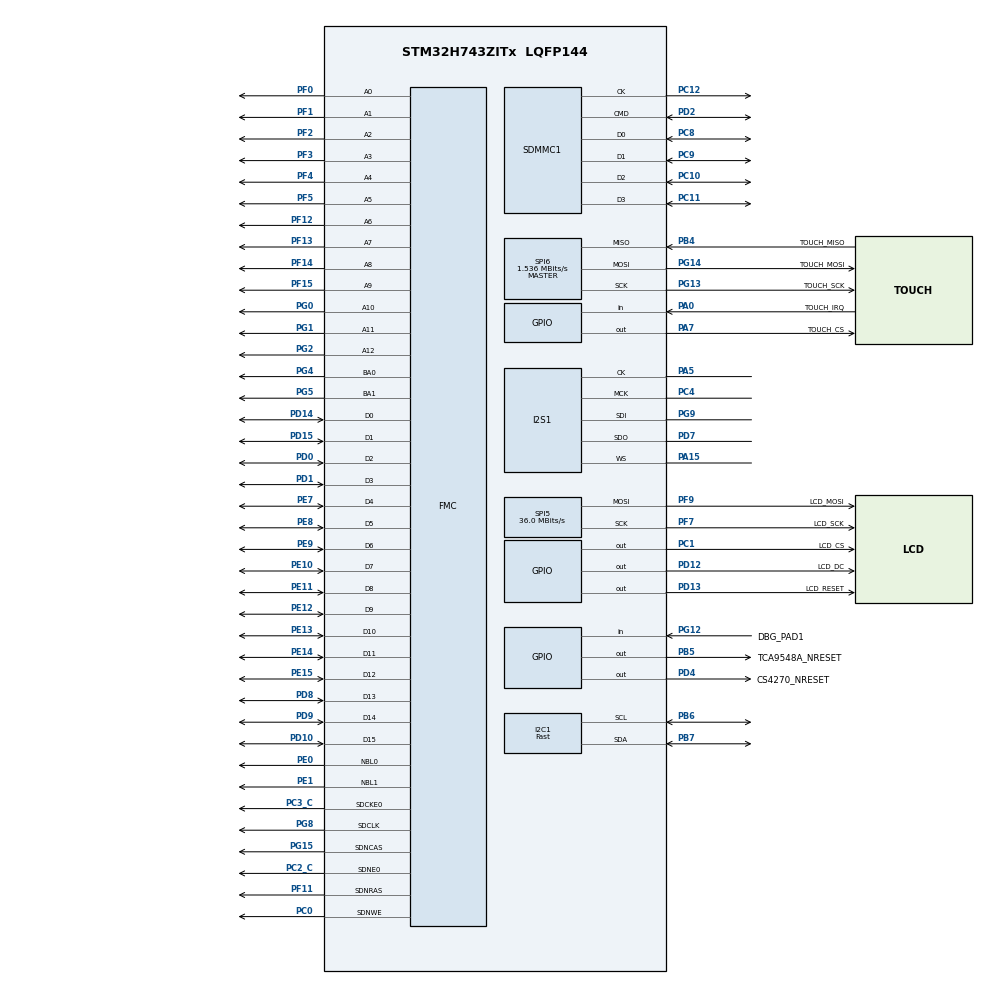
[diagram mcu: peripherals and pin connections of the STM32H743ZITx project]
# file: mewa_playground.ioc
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CORTEX_M7.AccessPermission-Cortex_Memory_Protection_Unit_Region0_Settings=MPU_REGION_FULL_ACCESS
CORTEX_M7.AccessPermission_S-Cortex_Memory_Protection_Unit_Region1_Settings_S=MPU_REGION_FULL_ACCESS
CORTEX_M7.AccessPermission_S-Cortex_Memory_Protection_Unit_Region2_Settings_S=MPU_REGION_FULL_ACCESS
CORTEX_M7.BaseAddress-Cortex_Memory_Protection_Unit_Region0_Settings=0xC0000000
CORTEX_M7.BaseAddress_S-Cortex_Memory_Protection_Unit_Region1_Settings_S=0x24000000
CORTEX_M7.BaseAddress_S-Cortex_Memory_Protection_Unit_Region2_Settings_S=0xC0000000
CORTEX_M7.CPU_DCache=Enabled
CORTEX_M7.CPU_ICache=Enabled
CORTEX_M7.DisableExec-Cortex_Memory_Protection_Unit_Region0_Settings=MPU_INSTRUCTION_ACCESS_DISABLE
CORTEX_M7.DisableExec_S-Cortex_Memory_Protection_Unit_Region1_Settings_S=MPU_INSTRUCTION_ACCESS_DISABLE
CORTEX_M7.DisableExec_S-Cortex_Memory_Protection_Unit_Region2_Settings_S=MPU_INSTRUCTION_ACCESS_DISABLE
CORTEX_M7.Enable-Cortex_Memory_Protection_Unit_Region0_Settings=MPU_REGION_ENABLE
CORTEX_M7.Enable_S-Cortex_Memory_Protection_Unit_Region1_Settings_S=MPU_REGION_ENABLE
CORTEX_M7.Enable_S-Cortex_Memory_Protection_Unit_Region2_Settings_S=MPU_REGION_ENABLE
CORTEX_M7.IsBufferable_S-Cortex_Memory_Protection_Unit_Region1_Settings_S=MPU_ACCESS_BUFFERABLE
CORTEX_M7.IsBufferable_S-Cortex_Memory_Protection_Unit_Region2_Settings_S=MPU_ACCESS_NOT_BUFFERABLE
CORTEX_M7.IsBufferable_Spec=MPU_ACCESS_NOT_BUFFERABLE
CORTEX_M7.IsCacheable_S-Cortex_Memory_Protection_Unit_Region1_Settings_S=MPU_ACCESS_CACHEABLE
CORTEX_M7.IsCacheable_S-Cortex_Memory_Protection_Unit_Region2_Settings_S=MPU_ACCESS_CACHEABLE
CORTEX_M7.IsCacheable_Spec=MPU_ACCESS_NOT_CACHEABLE
CORTEX_M7.IsShareable-Cortex_Memory_Protection_Unit_Region0_Settings=MPU_ACCESS_SHAREABLE
CORTEX_M7.IsShareable_S-Cortex_Memory_Protection_Unit_Region1_Settings_S=MPU_ACCESS_NOT_SHAREABLE
CORTEX_M7.IsShareable_Spec=MPU_ACCESS_NOT_SHAREABLE
CORTEX_M7.MPU_Control=MPU_PRIVILEGED_DEFAULT
CORTEX_M7.Size-Cortex_Memory_Protection_Unit_Region0_Settings=MPU_REGION_SIZE_32MB
CORTEX_M7.Size_S-Cortex_Memory_Protection_Unit_Region1_Settings_S=MPU_REGION_SIZE_512KB
CORTEX_M7.Size_S-Cortex_Memory_Protection_Unit_Region2_Settings_S=MPU_REGION_SIZE_32MB
CORTEX_M7.TypeExtField-Cortex_Memory_Protection_Unit_Region0_Settings=MPU_TEX_LEVEL1
CORTEX_M7.TypeExtField_S-Cortex_Memory_Protection_Unit_Region1_Settings_S=MPU_TEX_LEVEL1
CORTEX_M7.TypeExtField_S-Cortex_Memory_Protection_Unit_Region2_Settings_S=MPU_TEX_LEVEL0
CORTEX_M7.default_mode_Activation=1
Dma.Request0=SPI1_TX
Dma.Request1=SPI5_TX
Dma.SPI1_TX.0.Direction=DMA_MEMORY_TO_PERIPH
Dma.SPI1_TX.0.EventEnable=DISABLE
Dma.SPI1_TX.0.FIFOMode=DMA_FIFOMODE_DISABLE
Dma.SPI1_TX.0.Instance=DMA1_Stream0
Dma.SPI1_TX.0.MemDataAlignment=DMA_MDATAALIGN_HALFWORD
Dma.SPI1_TX.0.MemInc=DMA_MINC_ENABLE
Dma.SPI1_TX.0.Mode=DMA_CIRCULAR
Dma.SPI1_TX.0.PeriphDataAlignment=DMA_PDATAALIGN_HALFWORD
Dma.SPI1_TX.0.PeriphInc=DMA_PINC_DISABLE
Dma.SPI1_TX.0.Polarity=HAL_DMAMUX_REQ_GEN_RISING
Dma.SPI1_TX.0.Priority=DMA_PRIORITY_LOW
Dma.SPI1_TX.0.RequestNumber=1
Dma.SPI1_TX.0.SignalID=NONE
Dma.SPI1_TX.0.SyncEnable=DISABLE
Dma.SPI1_TX.0.SyncPolarity=HAL_DMAMUX_SYNC_NO_EVENT
Dma.SPI1_TX.0.SyncRequestNumber=1
Dma.SPI1_TX.0.SyncSignalID=NONE
Dma.SPI5_TX.1.Direction=DMA_MEMORY_TO_PERIPH
Dma.SPI5_TX.1.EventEnable=DISABLE
Dma.SPI5_TX.1.FIFOMode=DMA_FIFOMODE_DISABLE
Dma.SPI5_TX.1.Instance=DMA1_Stream1
Dma.SPI5_TX.1.MemDataAlignment=DMA_MDATAALIGN_BYTE
Dma.SPI5_TX.1.MemInc=DMA_MINC_ENABLE
Dma.SPI5_TX.1.Mode=DMA_NORMAL
Dma.SPI5_TX.1.PeriphDataAlignment=DMA_PDATAALIGN_BYTE
Dma.SPI5_TX.1.PeriphInc=DMA_PINC_DISABLE
Dma.SPI5_TX.1.Polarity=HAL_DMAMUX_REQ_GEN_RISING
Dma.SPI5_TX.1.Priority=DMA_PRIORITY_LOW
Dma.SPI5_TX.1.RequestNumber=1
Dma.SPI5_TX.1.SignalID=NONE
Dma.SPI5_TX.1.SyncEnable=DISABLE
Dma.SPI5_TX.1.SyncPolarity=HAL_DMAMUX_SYNC_NO_EVENT
Dma.SPI5_TX.1.SyncRequestNumber=1
Dma.SPI5_TX.1.SyncSignalID=NONE
FATFS.BSP.number=1
FATFS.USE_DMA_CODE_SD=1
FATFS._USE_FASTSEEK=1
FATFS._USE_LFN=3
FATFS._USE_MKFS=0
FATFS0.BSP.STBoard=false
FATFS0.BSP.api=Unknown
FATFS0.BSP.instance=PG12
FATFS0.BSP.ip=GPIO
FATFS0.BSP.mode=Input
FATFS0.BSP.name=Detect_SDIO
FATFS0.BSP.solution=PG12
FMC.BankMapConfig=FMC_SWAPBMAP_DISABLE
FMC.CASLatency1=FMC_SDRAM_CAS_LATENCY_2
FMC.ColumnBitsNumber1=FMC_SDRAM_COLUMN_BITS_NUM_9
FMC.ExitSelfRefreshDelay1=5
FMC.LoadToActiveDelay1=1
FMC.RCDDelay1=2
FMC.RPDelay1=2
FMC.RPDelay2=2
FMC.ReadBurst1=FMC_SDRAM_RBURST_ENABLE
FMC.ReadBurst2=FMC_SDRAM_RBURST_ENABLE
FMC.ReadPipeDelay1=FMC_SDRAM_RPIPE_DELAY_0
FMC.RowCycleDelay1=5
FMC.RowCycleDelay2=5
FMC.SDClockPeriod1=FMC_SDRAM_CLOCK_PERIOD_2
FMC.SDClockPeriod2=FMC_SDRAM_CLOCK_PERIOD_2
FMC.SelfRefreshTime1=4
FMC.WriteRecoveryTime1=2
I2C1.CustomTiming=Disabled
I2C1.I2C_Speed_Mode=I2C_Fast
I2C1.Timing=0x00702681
I2S1.AudioFreq=I2S_AUDIOFREQ_44K
I2S1.ErrorAudioFreq=0.22 %
I2S1.Instance=SPI$Index
I2S1.RealAudioFreq=44.1 KHz
Mcu.Family=STM32H7
Mcu.Name=STM32H743ZITx
Mcu.Package=LQFP144
Mdma.MDMA_Channel0.Request0=SDMMC1_END_DATA
Mdma.MDMA_Channel0.RequestsNb=1
Mdma.MDMA_Channel0.SDMMC1_END_DATA.0.BlockCount=0
Mdma.MDMA_Channel0.SDMMC1_END_DATA.0.BlockDataLength=0
Mdma.MDMA_Channel0.SDMMC1_END_DATA.0.BufferTransferLength=1
Mdma.MDMA_Channel0.SDMMC1_END_DATA.0.CircularMode=MDMA_LINEAR_LIST
Mdma.MDMA_Channel0.SDMMC1_END_DATA.0.DataAlignment=MDMA_DATAALIGN_PACKENABLE
Mdma.MDMA_Channel0.SDMMC1_END_DATA.0.DestBlockAddressOffset=0
Mdma.MDMA_Channel0.SDMMC1_END_DATA.0.DestBurst=MDMA_DEST_BURST_SINGLE
Mdma.MDMA_Channel0.SDMMC1_END_DATA.0.DestDataSize=MDMA_DEST_DATASIZE_BYTE
Mdma.MDMA_Channel0.SDMMC1_END_DATA.0.DestinationInc=MDMA_DEST_INC_BYTE
Mdma.MDMA_Channel0.SDMMC1_END_DATA.0.DstAddress=0
Mdma.MDMA_Channel0.SDMMC1_END_DATA.0.Endianness=MDMA_LITTLE_ENDIANNESS_PRESERVE
Mdma.MDMA_Channel0.SDMMC1_END_DATA.0.Instance=MDMA_Channel0
Mdma.MDMA_Channel0.SDMMC1_END_DATA.0.MaskAddress=0
Mdma.MDMA_Channel0.SDMMC1_END_DATA.0.MaskData=0
Mdma.MDMA_Channel0.SDMMC1_END_DATA.0.Priority=MDMA_PRIORITY_LOW
Mdma.MDMA_Channel0.SDMMC1_END_DATA.0.Rank=First
Mdma.MDMA_Channel0.SDMMC1_END_DATA.0.SourceBlockAddressOffset=0
Mdma.MDMA_Channel0.SDMMC1_END_DATA.0.SourceBurst=MDMA_SOURCE_BURST_SINGLE
Mdma.MDMA_Channel0.SDMMC1_END_DATA.0.SourceDataSize=MDMA_SRC_DATASIZE_BYTE
Mdma.MDMA_Channel0.SDMMC1_END_DATA.0.SourceInc=MDMA_SRC_INC_BYTE
Mdma.MDMA_Channel0.SDMMC1_END_DATA.0.SrcAddress=0
Mdma.MDMA_Channel0.SDMMC1_END_DATA.0.TransferTriggerMode=MDMA_BUFFER_TRANSFER
Mdma.RequestSet0=MDMA_Channel0
Mdma.RequestSetsNb=1
NVIC.DMA1_Stream0_IRQn=true\:0\:0\:false\:false\:true\:false\:true\:true
NVIC.DMA1_Stream1_IRQn=true\:0\:0\:false\:false\:true\:false\:true\:true
NVIC.MDMA_IRQn=true\:0\:0\:false\:false\:true\:false\:true\:true
NVIC.PriorityGroup=NVIC_PRIORITYGROUP_4
NVIC.SDMMC1_IRQn=true\:0\:0\:false\:false\:true\:true\:true\:true
NVIC.SPI5_IRQn=true\:0\:0\:false\:false\:true\:false\:true\:true
PA0.GPIO_Label=TOUCH_IRQ
PA0.GPIO_PuPd=GPIO_PULLUP
PA0.Signal=GPIO_Input
PA15\ (JTDI).Mode=Full_Duplex_Master
PA15\ (JTDI).Signal=I2S1_WS
PA5.Mode=Full_Duplex_Master
PA5.Signal=I2S1_CK
PA7.GPIO_Label=TOUCH_CS
PA7.GPIO_Speed=GPIO_SPEED_FREQ_LOW
PA7.PinState=GPIO_PIN_SET
PA7.Signal=GPIO_Output
PB4\ (NJTRST).GPIO_Label=TOUCH_MISO
PB4\ (NJTRST).GPIO_Speed=GPIO_SPEED_FREQ_LOW
PB4\ (NJTRST).Mode=Full_Duplex_Master
PB4\ (NJTRST).Signal=SPI6_MISO
PB5.GPIO_Label=TCA9548A_NRESET
PB5.Signal=GPIO_Output
PB6.Mode=I2C
PB6.Signal=I2C1_SCL
PB7.Mode=I2C
PB7.Signal=I2C1_SDA
PC0.Signal=FMC_SDNWE
PC1.GPIO_Label=LCD_CS
PC1.GPIO_Speed=GPIO_SPEED_FREQ_MEDIUM
PC1.PinState=GPIO_PIN_SET
PC1.Signal=GPIO_Output
PC10.Mode=SD_4_bits_Wide_bus
PC10.Signal=SDMMC1_D2
PC11.Mode=SD_4_bits_Wide_bus
PC11.Signal=SDMMC1_D3
PC12.Mode=SD_4_bits_Wide_bus
PC12.Signal=SDMMC1_CK
PC2_C.Mode=SdramChipSelect1_1
PC2_C.Signal=FMC_SDNE0
PC3_C.Mode=SdramChipSelect1_1
PC3_C.Signal=FMC_SDCKE0
PC4.Mode=Master_Clock_Activated
PC4.Signal=I2S1_MCK
PC8.Mode=SD_4_bits_Wide_bus
PC8.Signal=SDMMC1_D0
PC9.Mode=SD_4_bits_Wide_bus
PC9.Signal=SDMMC1_D1
PD0.Signal=FMC_D2_DA2
PD1.Signal=FMC_D3_DA3
PD10.Signal=FMC_D15_DA15
PD12.GPIO_Label=LCD_DC
PD12.GPIO_Speed=GPIO_SPEED_FREQ_MEDIUM
PD12.PinState=GPIO_PIN_RESET
PD12.Signal=GPIO_Output
PD13.GPIO_Label=LCD_RESET
PD13.GPIO_Speed=GPIO_SPEED_FREQ_MEDIUM
PD13.PinState=GPIO_PIN_RESET
PD13.Signal=GPIO_Output
PD14.Signal=FMC_D0_DA0
PD15.Signal=FMC_D1_DA1
PD2.Mode=SD_4_bits_Wide_bus
PD2.Signal=SDMMC1_CMD
PD4.GPIO_Label=CS4270_NRESET
PD4.Signal=GPIO_Output
PD7.Mode=Full_Duplex_Master
PD7.Signal=I2S1_SDO
PD8.Signal=FMC_D13_DA13
PD9.Signal=FMC_D14_DA14
PE0.Signal=FMC_NBL0
PE1.Signal=FMC_NBL1
PE10.Signal=FMC_D7_DA7
PE11.Signal=FMC_D8_DA8
PE12.Signal=FMC_D9_DA9
PE13.Signal=FMC_D10_DA10
PE14.Signal=FMC_D11_DA11
PE15.Signal=FMC_D12_DA12
PE7.Signal=FMC_D4_DA4
PE8.Signal=FMC_D5_DA5
PE9.Signal=FMC_D6_DA6
PF0.Signal=FMC_A0
PF1.Signal=FMC_A1
PF11.Signal=FMC_SDNRAS
PF12.Signal=FMC_A6
PF13.Signal=FMC_A7
PF14.Signal=FMC_A8
PF15.Signal=FMC_A9
PF2.Signal=FMC_A2
PF3.Signal=FMC_A3
PF4.Signal=FMC_A4
PF5.Signal=FMC_A5
PF7.GPIO_Label=LCD_SCK
PF7.GPIO_Speed=GPIO_SPEED_FREQ_MEDIUM
PF7.Mode=TX_Only_Simplex_Unidirect_Master
PF7.Signal=SPI5_SCK
PF9.GPIO_Label=LCD_MOSI
PF9.GPIO_Speed=GPIO_SPEED_FREQ_MEDIUM
PF9.Mode=TX_Only_Simplex_Unidirect_Master
PF9.Signal=SPI5_MOSI
PG0.Signal=FMC_A10
PG1.Signal=FMC_A11
PG12.GPIO_Label=DBG_PAD1
PG12.GPIO_PuPd=GPIO_PULLDOWN
PG12.Signal=GPIO_Input
PG13.GPIO_Label=TOUCH_SCK
PG13.GPIO_Speed=GPIO_SPEED_FREQ_LOW
PG13.Mode=Full_Duplex_Master
PG13.Signal=SPI6_SCK
PG14.GPIO_Label=TOUCH_MOSI
PG14.GPIO_Speed=GPIO_SPEED_FREQ_LOW
PG14.Mode=Full_Duplex_Master
PG14.Signal=SPI6_MOSI
PG15.Signal=FMC_SDNCAS
PG2.Signal=FMC_A12
PG4.Signal=FMC_A14_BA0
PG5.Signal=FMC_A15_BA1
PG8.Signal=FMC_SDCLK
PG9.Mode=Full_Duplex_Master
PG9.Signal=I2S1_SDI
PH0-OSC_IN\ (PH0).Mode=HSE-External-Oscillator
PH0-OSC_IN\ (PH0).Signal=RCC_OSC_IN
PH1-OSC_OUT\ (PH1).Mode=HSE-External-Oscillator
PH1-OSC_OUT\ (PH1).Signal=RCC_OSC_OUT
ProjectManager.HeapSize=0x20000
ProjectManager.StackSize=0x6000
ProjectManager.TargetToolchain=STM32CubeIDE
RCC.ADCFreq_Value=90316800
RCC.APB1Freq_Value=72000000
RCC.APB2Freq_Value=72000000
RCC.APB3Freq_Value=72000000
RCC.APB4Freq_Value=72000000
RCC.CKPERSourceSelection=RCC_CLKPSOURCE_HSE
RCC.CortexFreq_Value=18000000
RCC.Cortex_Div=SYSTICK_CLKSOURCE_HCLK_DIV8
RCC.D1PPRE=RCC_APB3_DIV2
RCC.D2PPRE1=RCC_APB1_DIV2
RCC.D2PPRE2=RCC_APB2_DIV2
RCC.D3PPRE=RCC_APB4_DIV2
RCC.DIVM1=1
RCC.DIVM2=1
RCC.DIVN1=23
RCC.DIVN2=36
RCC.DIVP2=5
RCC.DIVQ1=12
RCC.DIVQ2=5
RCC.DIVR2=5
RCC.HCLKFreq_Value=144000000
RCC.HSE_VALUE=12288000
RCC.PLL2FRACN=6144
RCC.PLL3FRACN=0
RCC.PLLFRACN=3584
RCC.PLLSourceVirtual=RCC_PLLSOURCE_HSE
RCC.PWR_Regulator_Voltage_Scale=PWR_REGULATOR_VOLTAGE_SCALE2
RCC.SPI123CLockSelection=RCC_SPI123CLKSOURCE_PLL2
RCC.SPI6CLockSelection=RCC_SPI6CLKSOURCE_HSE
RCC.SYSCLKFreq_VALUE=144000000
RCC.SYSCLKSource=RCC_SYSCLKSOURCE_PLLCLK
RCC.USBFreq_Value=24000000
SDMMC1.ClockDiv=0
SH.FMC_A0.0=FMC_A0,13b-sda1
SH.FMC_A1.0=FMC_A1,13b-sda1
SH.FMC_A10.0=FMC_A10,13b-sda1
SH.FMC_A11.0=FMC_A11,13b-sda1
SH.FMC_A12.0=FMC_A12,13b-sda1
SH.FMC_A14_BA0.0=FMC_BA0,FourSdramBanks1
SH.FMC_A15_BA1.0=FMC_BA1,FourSdramBanks1
SH.FMC_A2.0=FMC_A2,13b-sda1
SH.FMC_A3.0=FMC_A3,13b-sda1
SH.FMC_A4.0=FMC_A4,13b-sda1
SH.FMC_A5.0=FMC_A5,13b-sda1
SH.FMC_A6.0=FMC_A6,13b-sda1
SH.FMC_A7.0=FMC_A7,13b-sda1
SH.FMC_A8.0=FMC_A8,13b-sda1
SH.FMC_A9.0=FMC_A9,13b-sda1
SH.FMC_D0_DA0.0=FMC_D0,sd-16b-d1
SH.FMC_D10_DA10.0=FMC_D10,sd-16b-d1
SH.FMC_D11_DA11.0=FMC_D11,sd-16b-d1
SH.FMC_D12_DA12.0=FMC_D12,sd-16b-d1
SH.FMC_D13_DA13.0=FMC_D13,sd-16b-d1
SH.FMC_D14_DA14.0=FMC_D14,sd-16b-d1
SH.FMC_D15_DA15.0=FMC_D15,sd-16b-d1
SH.FMC_D1_DA1.0=FMC_D1,sd-16b-d1
SH.FMC_D2_DA2.0=FMC_D2,sd-16b-d1
SH.FMC_D3_DA3.0=FMC_D3,sd-16b-d1
SH.FMC_D4_DA4.0=FMC_D4,sd-16b-d1
SH.FMC_D5_DA5.0=FMC_D5,sd-16b-d1
SH.FMC_D6_DA6.0=FMC_D6,sd-16b-d1
SH.FMC_D7_DA7.0=FMC_D7,sd-16b-d1
SH.FMC_D8_DA8.0=FMC_D8,sd-16b-d1
SH.FMC_D9_DA9.0=FMC_D9,sd-16b-d1
SH.FMC_NBL0.0=FMC_NBL0,Sd2ByteEnable1
SH.FMC_NBL1.0=FMC_NBL1,Sd2ByteEnable1
SH.FMC_SDCLK.0=FMC_SDCLK,13b-sda1
SH.FMC_SDNCAS.0=FMC_SDNCAS,13b-sda1
SH.FMC_SDNRAS.0=FMC_SDNRAS,13b-sda1
SH.FMC_SDNWE.0=FMC_SDNWE,13b-sda1
SPI5.BaudRatePrescaler=SPI_BAUDRATEPRESCALER_2
SPI5.CalculateBaudRate=36.0 MBits/s
SPI5.DataSize=SPI_DATASIZE_8BIT
SPI5.Direction=SPI_DIRECTION_2LINES_TXONLY
SPI5.MasterKeepIOState=SPI_MASTER_KEEP_IO_STATE_ENABLE
SPI5.Mode=SPI_MODE_MASTER
SPI5.NSSPMode=SPI_NSS_PULSE_DISABLE
SPI5.VirtualType=VM_MASTER
SPI6.BaudRatePrescaler=SPI_BAUDRATEPRESCALER_8
SPI6.CalculateBaudRate=1.536 MBits/s
SPI6.DataSize=SPI_DATASIZE_8BIT
SPI6.Direction=SPI_DIRECTION_2LINES
SPI6.MasterKeepIOState=SPI_MASTER_KEEP_IO_STATE_DISABLE
SPI6.Mode=SPI_MODE_MASTER
SPI6.NSSPMode=SPI_NSS_PULSE_DISABLE
SPI6.VirtualType=VM_MASTER
VP_FATFS_VS_SDIO.Mode=SDIO
board=custom

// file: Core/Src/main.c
/* USER CODE BEGIN Header */
/**
  ******************************************************************************
  * @file           : main.c
  * @brief          : Main program body
  ******************************************************************************
  * @attention
  *
  * Copyright (c) 2023 STMicroelectronics.
  * All rights reserved.
  *
  * This software is licensed under terms that can be found in the LICENSE file
  * in the root directory of this software component.
  * If no LICENSE file comes with this software, it is provided AS-IS.
  *
  ******************************************************************************
  */
/* USER CODE END Header */
#include "main.h"
#include "fatfs.h"

/* USER CODE BEGIN Includes */
#include <stdbool.h>
#include "sdram.h"
#include "lvgl_init.h"
#include "lvgl.h"
#include "gui.h"
#include "player.h"
#include "cs4270.h"
/* USER CODE END Includes */

I2C_HandleTypeDef hi2c1;

I2S_HandleTypeDef hi2s1;
DMA_HandleTypeDef hdma_spi1_tx;

SD_HandleTypeDef hsd1;

SPI_HandleTypeDef hspi5;
SPI_HandleTypeDef hspi6;
DMA_HandleTypeDef hdma_spi5_tx;

MDMA_HandleTypeDef hmdma_mdma_channel40_sdmmc1_end_data_0;
SDRAM_HandleTypeDef hsdram1;

/* USER CODE BEGIN PV */

static FATFS __attribute__((section(".sdram"))) fatfs;

/* USER CODE END PV */

void SystemClock_Config(void);
static void MPU_Config(void);
static void MX_GPIO_Init(void);
static void MX_DMA_Init(void);
static void MX_MDMA_Init(void);
static void MX_I2S1_Init(void);
static void MX_SDMMC1_SD_Init(void);
static void MX_I2C1_Init(void);
static void MX_FMC_Init(void);
static void MX_SPI6_Init(void);
static void MX_SPI5_Init(void);

int main(void)
{
  /* USER CODE BEGIN 1 */
  const char *const mount_point = "/";
  /* USER CODE END 1 */

  /* MPU Configuration--------------------------------------------------------*/
  MPU_Config();

  /* Enable I-Cache---------------------------------------------------------*/
  SCB_EnableICache();

  /* Enable D-Cache---------------------------------------------------------*/
  SCB_EnableDCache();

  /* MCU Configuration--------------------------------------------------------*/

  /* Reset of all peripherals, Initializes the Flash interface and the Systick. */
  HAL_Init();

  /* Configure the system clock */
  SystemClock_Config();

  /* Initialize all configured peripherals */
  MX_GPIO_Init();
  MX_DMA_Init();
  MX_MDMA_Init();
  MX_I2S1_Init();
  MX_SDMMC1_SD_Init();
  MX_I2C1_Init();
  MX_FATFS_Init();
  MX_FMC_Init();
  MX_SPI6_Init();
  MX_SPI5_Init();
  /* USER CODE BEGIN 2 */

//  i2cmux_init();
  const bool mount_ok = (f_mount(&fatfs, mount_point, 1) == FR_OK);

  cs4270_init();
  player_init(&hi2s1, &hi2c1);
  gui_init(mount_ok);

  /* USER CODE END 2 */

  /* Infinite loop */
  /* USER CODE BEGIN WHILE */
  while (1)
  {
	  gui_task();
	  player_task();
    /* USER CODE END WHILE */

  }
}

void SystemClock_Config(void)
{
  RCC_OscInitTypeDef RCC_OscInitStruct = {0};
  RCC_ClkInitTypeDef RCC_ClkInitStruct = {0};

  /** Supply configuration update enable
  */
  HAL_PWREx_ConfigSupply(PWR_LDO_SUPPLY);

  /** Configure the main internal regulator output voltage
  */
  __HAL_PWR_VOLTAGESCALING_CONFIG(PWR_REGULATOR_VOLTAGE_SCALE2);

  while(!__HAL_PWR_GET_FLAG(PWR_FLAG_VOSRDY)) {}

  /** Macro to configure the PLL clock source
  */
  __HAL_RCC_PLL_PLLSOURCE_CONFIG(RCC_PLLSOURCE_HSE);

  /** Initializes the RCC Oscillators according to the specified parameters
  * in the RCC_OscInitTypeDef structure.
  */
  RCC_OscInitStruct.OscillatorType = RCC_OSCILLATORTYPE_HSE;
  RCC_OscInitStruct.HSEState = RCC_HSE_ON;
  RCC_OscInitStruct.PLL.PLLState = RCC_PLL_ON;
  RCC_OscInitStruct.PLL.PLLSource = RCC_PLLSOURCE_HSE;
  RCC_OscInitStruct.PLL.PLLM = 1;
  RCC_OscInitStruct.PLL.PLLN = 23;
  RCC_OscInitStruct.PLL.PLLP = 2;
  RCC_OscInitStruct.PLL.PLLQ = 12;
  RCC_OscInitStruct.PLL.PLLR = 2;
  RCC_OscInitStruct.PLL.PLLRGE = RCC_PLL1VCIRANGE_3;
  RCC_OscInitStruct.PLL.PLLVCOSEL = RCC_PLL1VCOWIDE;
  RCC_OscInitStruct.PLL.PLLFRACN = 3584;
  if (HAL_RCC_OscConfig(&RCC_OscInitStruct) != HAL_OK)
  {
    Error_Handler();
  }

  /** Initializes the CPU, AHB and APB buses clocks
  */
  RCC_ClkInitStruct.ClockType = RCC_CLOCKTYPE_HCLK|RCC_CLOCKTYPE_SYSCLK
                              |RCC_CLOCKTYPE_PCLK1|RCC_CLOCKTYPE_PCLK2
                              |RCC_CLOCKTYPE_D3PCLK1|RCC_CLOCKTYPE_D1PCLK1;
  RCC_ClkInitStruct.SYSCLKSource = RCC_SYSCLKSOURCE_PLLCLK;
  RCC_ClkInitStruct.SYSCLKDivider = RCC_SYSCLK_DIV1;
  RCC_ClkInitStruct.AHBCLKDivider = RCC_HCLK_DIV1;
  RCC_ClkInitStruct.APB3CLKDivider = RCC_APB3_DIV2;
  RCC_ClkInitStruct.APB1CLKDivider = RCC_APB1_DIV2;
  RCC_ClkInitStruct.APB2CLKDivider = RCC_APB2_DIV2;
  RCC_ClkInitStruct.APB4CLKDivider = RCC_APB4_DIV2;

  if (HAL_RCC_ClockConfig(&RCC_ClkInitStruct, FLASH_LATENCY_2) != HAL_OK)
  {
    Error_Handler();
  }
}

static void MX_I2C1_Init(void)
{

  hi2c1.Instance = I2C1;
  hi2c1.Init.Timing = 0x00702681;
  hi2c1.Init.OwnAddress1 = 0;
  hi2c1.Init.AddressingMode = I2C_ADDRESSINGMODE_7BIT;
  hi2c1.Init.DualAddressMode = I2C_DUALADDRESS_DISABLE;
  hi2c1.Init.OwnAddress2 = 0;
  hi2c1.Init.OwnAddress2Masks = I2C_OA2_NOMASK;
  hi2c1.Init.GeneralCallMode = I2C_GENERALCALL_DISABLE;
  hi2c1.Init.NoStretchMode = I2C_NOSTRETCH_DISABLE;
  if (HAL_I2C_Init(&hi2c1) != HAL_OK)
  {
    Error_Handler();
  }

  /** Configure Analogue filter
  */
  if (HAL_I2CEx_ConfigAnalogFilter(&hi2c1, I2C_ANALOGFILTER_ENABLE) != HAL_OK)
  {
    Error_Handler();
  }

  /** Configure Digital filter
  */
  if (HAL_I2CEx_ConfigDigitalFilter(&hi2c1, 0) != HAL_OK)
  {
    Error_Handler();
  }

}

static void MX_I2S1_Init(void)
{

  hi2s1.Instance = SPI1;
  hi2s1.Init.Mode = I2S_MODE_MASTER_FULLDUPLEX;
  hi2s1.Init.Standard = I2S_STANDARD_PHILIPS;
  hi2s1.Init.DataFormat = I2S_DATAFORMAT_16B;
  hi2s1.Init.MCLKOutput = I2S_MCLKOUTPUT_ENABLE;
  hi2s1.Init.AudioFreq = I2S_AUDIOFREQ_44K;
  hi2s1.Init.CPOL = I2S_CPOL_LOW;
  hi2s1.Init.FirstBit = I2S_FIRSTBIT_MSB;
  hi2s1.Init.WSInversion = I2S_WS_INVERSION_DISABLE;
  hi2s1.Init.Data24BitAlignment = I2S_DATA_24BIT_ALIGNMENT_RIGHT;
  hi2s1.Init.MasterKeepIOState = I2S_MASTER_KEEP_IO_STATE_DISABLE;
  if (HAL_I2S_Init(&hi2s1) != HAL_OK)
  {
    Error_Handler();
  }

}

static void MX_SDMMC1_SD_Init(void)
{

  hsd1.Instance = SDMMC1;
  hsd1.Init.ClockEdge = SDMMC_CLOCK_EDGE_RISING;
  hsd1.Init.ClockPowerSave = SDMMC_CLOCK_POWER_SAVE_DISABLE;
  hsd1.Init.BusWide = SDMMC_BUS_WIDE_4B;
  hsd1.Init.HardwareFlowControl = SDMMC_HARDWARE_FLOW_CONTROL_DISABLE;
  hsd1.Init.ClockDiv = 0;

}

static void MX_SPI5_Init(void)
{

  /* SPI5 parameter configuration*/
  hspi5.Instance = SPI5;
  hspi5.Init.Mode = SPI_MODE_MASTER;
  hspi5.Init.Direction = SPI_DIRECTION_2LINES_TXONLY;
  hspi5.Init.DataSize = SPI_DATASIZE_8BIT;
  hspi5.Init.CLKPolarity = SPI_POLARITY_LOW;
  hspi5.Init.CLKPhase = SPI_PHASE_1EDGE;
  hspi5.Init.NSS = SPI_NSS_SOFT;
  hspi5.Init.BaudRatePrescaler = SPI_BAUDRATEPRESCALER_2;
  hspi5.Init.FirstBit = SPI_FIRSTBIT_MSB;
  hspi5.Init.TIMode = SPI_TIMODE_DISABLE;
  hspi5.Init.CRCCalculation = SPI_CRCCALCULATION_DISABLE;
  hspi5.Init.CRCPolynomial = 0x0;
  hspi5.Init.NSSPMode = SPI_NSS_PULSE_DISABLE;
  hspi5.Init.NSSPolarity = SPI_NSS_POLARITY_LOW;
  hspi5.Init.FifoThreshold = SPI_FIFO_THRESHOLD_01DATA;
  hspi5.Init.TxCRCInitializationPattern = SPI_CRC_INITIALIZATION_ALL_ZERO_PATTERN;
  hspi5.Init.RxCRCInitializationPattern = SPI_CRC_INITIALIZATION_ALL_ZERO_PATTERN;
  hspi5.Init.MasterSSIdleness = SPI_MASTER_SS_IDLENESS_00CYCLE;
  hspi5.Init.MasterInterDataIdleness = SPI_MASTER_INTERDATA_IDLENESS_00CYCLE;
  hspi5.Init.MasterReceiverAutoSusp = SPI_MASTER_RX_AUTOSUSP_DISABLE;
  hspi5.Init.MasterKeepIOState = SPI_MASTER_KEEP_IO_STATE_ENABLE;
  hspi5.Init.IOSwap = SPI_IO_SWAP_DISABLE;
  if (HAL_SPI_Init(&hspi5) != HAL_OK)
  {
    Error_Handler();
  }

}

static void MX_SPI6_Init(void)
{

  /* SPI6 parameter configuration*/
  hspi6.Instance = SPI6;
  hspi6.Init.Mode = SPI_MODE_MASTER;
  hspi6.Init.Direction = SPI_DIRECTION_2LINES;
  hspi6.Init.DataSize = SPI_DATASIZE_8BIT;
  hspi6.Init.CLKPolarity = SPI_POLARITY_LOW;
  hspi6.Init.CLKPhase = SPI_PHASE_1EDGE;
  hspi6.Init.NSS = SPI_NSS_SOFT;
  hspi6.Init.BaudRatePrescaler = SPI_BAUDRATEPRESCALER_8;
  hspi6.Init.FirstBit = SPI_FIRSTBIT_MSB;
  hspi6.Init.TIMode = SPI_TIMODE_DISABLE;
  hspi6.Init.CRCCalculation = SPI_CRCCALCULATION_DISABLE;
  hspi6.Init.CRCPolynomial = 0x0;
  hspi6.Init.NSSPMode = SPI_NSS_PULSE_DISABLE;
  hspi6.Init.NSSPolarity = SPI_NSS_POLARITY_LOW;
  hspi6.Init.FifoThreshold = SPI_FIFO_THRESHOLD_01DATA;
  hspi6.Init.TxCRCInitializationPattern = SPI_CRC_INITIALIZATION_ALL_ZERO_PATTERN;
  hspi6.Init.RxCRCInitializationPattern = SPI_CRC_INITIALIZATION_ALL_ZERO_PATTERN;
  hspi6.Init.MasterSSIdleness = SPI_MASTER_SS_IDLENESS_00CYCLE;
  hspi6.Init.MasterInterDataIdleness = SPI_MASTER_INTERDATA_IDLENESS_00CYCLE;
  hspi6.Init.MasterReceiverAutoSusp = SPI_MASTER_RX_AUTOSUSP_DISABLE;
  hspi6.Init.MasterKeepIOState = SPI_MASTER_KEEP_IO_STATE_DISABLE;
  hspi6.Init.IOSwap = SPI_IO_SWAP_DISABLE;
  if (HAL_SPI_Init(&hspi6) != HAL_OK)
  {
    Error_Handler();
  }

}

static void MX_DMA_Init(void)
{

  /* DMA controller clock enable */
  __HAL_RCC_DMA1_CLK_ENABLE();

  /* DMA interrupt init */
  /* DMA1_Stream0_IRQn interrupt configuration */
  HAL_NVIC_SetPriority(DMA1_Stream0_IRQn, 0, 0);
  HAL_NVIC_EnableIRQ(DMA1_Stream0_IRQn);
  /* DMA1_Stream1_IRQn interrupt configuration */
  HAL_NVIC_SetPriority(DMA1_Stream1_IRQn, 0, 0);
  HAL_NVIC_EnableIRQ(DMA1_Stream1_IRQn);

}

/**
  * Enable MDMA controller clock
  * Configure MDMA for global transfers
  *   hmdma_mdma_channel40_sdmmc1_end_data_0
  */
static void MX_MDMA_Init(void)
{

  /* MDMA controller clock enable */
  __HAL_RCC_MDMA_CLK_ENABLE();
  /* Local variables */

  /* Configure MDMA channel MDMA_Channel0 */
  /* Configure MDMA request hmdma_mdma_channel40_sdmmc1_end_data_0 on MDMA_Channel0 */
  hmdma_mdma_channel40_sdmmc1_end_data_0.Instance = MDMA_Channel0;
  hmdma_mdma_channel40_sdmmc1_end_data_0.Init.Request = MDMA_REQUEST_SDMMC1_END_DATA;
  hmdma_mdma_channel40_sdmmc1_end_data_0.Init.TransferTriggerMode = MDMA_BUFFER_TRANSFER;
  hmdma_mdma_channel40_sdmmc1_end_data_0.Init.Priority = MDMA_PRIORITY_LOW;
  hmdma_mdma_channel40_sdmmc1_end_data_0.Init.Endianness = MDMA_LITTLE_ENDIANNESS_PRESERVE;
  hmdma_mdma_channel40_sdmmc1_end_data_0.Init.SourceInc = MDMA_SRC_INC_BYTE;
  hmdma_mdma_channel40_sdmmc1_end_data_0.Init.DestinationInc = MDMA_DEST_INC_BYTE;
  hmdma_mdma_channel40_sdmmc1_end_data_0.Init.SourceDataSize = MDMA_SRC_DATASIZE_BYTE;
  hmdma_mdma_channel40_sdmmc1_end_data_0.Init.DestDataSize = MDMA_DEST_DATASIZE_BYTE;
  hmdma_mdma_channel40_sdmmc1_end_data_0.Init.DataAlignment = MDMA_DATAALIGN_PACKENABLE;
  hmdma_mdma_channel40_sdmmc1_end_data_0.Init.BufferTransferLength = 1;
  hmdma_mdma_channel40_sdmmc1_end_data_0.Init.SourceBurst = MDMA_SOURCE_BURST_SINGLE;
  hmdma_mdma_channel40_sdmmc1_end_data_0.Init.DestBurst = MDMA_DEST_BURST_SINGLE;
  hmdma_mdma_channel40_sdmmc1_end_data_0.Init.SourceBlockAddressOffset = 0;
  hmdma_mdma_channel40_sdmmc1_end_data_0.Init.DestBlockAddressOffset = 0;
  if (HAL_MDMA_Init(&hmdma_mdma_channel40_sdmmc1_end_data_0) != HAL_OK)
  {
    Error_Handler();
  }

  /* Configure post request address and data masks */
  if (HAL_MDMA_ConfigPostRequestMask(&hmdma_mdma_channel40_sdmmc1_end_data_0, 0, 0) != HAL_OK)
  {
    Error_Handler();
  }

  /* MDMA interrupt initialization */
  /* MDMA_IRQn interrupt configuration */
  HAL_NVIC_SetPriority(MDMA_IRQn, 0, 0);
  HAL_NVIC_EnableIRQ(MDMA_IRQn);

}

/* FMC initialization function */
static void MX_FMC_Init(void)
{

  FMC_SDRAM_TimingTypeDef SdramTiming = {0};

  /** Perform the SDRAM1 memory initialization sequence
  */
  hsdram1.Instance = FMC_SDRAM_DEVICE;
  /* hsdram1.Init */
  hsdram1.Init.SDBank = FMC_SDRAM_BANK1;
  hsdram1.Init.ColumnBitsNumber = FMC_SDRAM_COLUMN_BITS_NUM_9;
  hsdram1.Init.RowBitsNumber = FMC_SDRAM_ROW_BITS_NUM_13;
  hsdram1.Init.MemoryDataWidth = FMC_SDRAM_MEM_BUS_WIDTH_16;
  hsdram1.Init.InternalBankNumber = FMC_SDRAM_INTERN_BANKS_NUM_4;
  hsdram1.Init.CASLatency = FMC_SDRAM_CAS_LATENCY_2;
  hsdram1.Init.WriteProtection = FMC_SDRAM_WRITE_PROTECTION_DISABLE;
  hsdram1.Init.SDClockPeriod = FMC_SDRAM_CLOCK_PERIOD_2;
  hsdram1.Init.ReadBurst = FMC_SDRAM_RBURST_ENABLE;
  hsdram1.Init.ReadPipeDelay = FMC_SDRAM_RPIPE_DELAY_0;
  /* SdramTiming */
  SdramTiming.LoadToActiveDelay = 1;
  SdramTiming.ExitSelfRefreshDelay = 5;
  SdramTiming.SelfRefreshTime = 4;
  SdramTiming.RowCycleDelay = 5;
  SdramTiming.WriteRecoveryTime = 2;
  SdramTiming.RPDelay = 2;
  SdramTiming.RCDDelay = 2;

  if (HAL_SDRAM_Init(&hsdram1, &SdramTiming) != HAL_OK)
  {
    Error_Handler( );
  }

  /* USER CODE BEGIN FMC_Init 2 */
  sdram_init(&hsdram1);
  /* USER CODE END FMC_Init 2 */
}

static void MX_GPIO_Init(void)
{
  GPIO_InitTypeDef GPIO_InitStruct = {0};

  /* GPIO Ports Clock Enable */
  __HAL_RCC_GPIOF_CLK_ENABLE();
  __HAL_RCC_GPIOH_CLK_ENABLE();
  __HAL_RCC_GPIOC_CLK_ENABLE();
  __HAL_RCC_GPIOA_CLK_ENABLE();
  __HAL_RCC_GPIOG_CLK_ENABLE();
  __HAL_RCC_GPIOE_CLK_ENABLE();
  __HAL_RCC_GPIOD_CLK_ENABLE();
  __HAL_RCC_GPIOB_CLK_ENABLE();

  /*Configure GPIO pin Output Level */
  HAL_GPIO_WritePin(LCD_CS_GPIO_Port, LCD_CS_Pin, GPIO_PIN_SET);

  /*Configure GPIO pin Output Level */
  HAL_GPIO_WritePin(TOUCH_CS_GPIO_Port, TOUCH_CS_Pin, GPIO_PIN_SET);

  /*Configure GPIO pin Output Level */
  HAL_GPIO_WritePin(GPIOD, LCD_DC_Pin|LCD_RESET_Pin|CS4270_NRESET_Pin, GPIO_PIN_RESET);

  /*Configure GPIO pin Output Level */
  HAL_GPIO_WritePin(TCA9548A_NRESET_GPIO_Port, TCA9548A_NRESET_Pin, GPIO_PIN_RESET);

  /*Configure GPIO pin : LCD_CS_Pin */
  GPIO_InitStruct.Pin = LCD_CS_Pin;
  GPIO_InitStruct.Mode = GPIO_MODE_OUTPUT_PP;
  GPIO_InitStruct.Pull = GPIO_NOPULL;
  GPIO_InitStruct.Speed = GPIO_SPEED_FREQ_MEDIUM;
  HAL_GPIO_Init(LCD_CS_GPIO_Port, &GPIO_InitStruct);

  /*Configure GPIO pin : TOUCH_IRQ_Pin */
  GPIO_InitStruct.Pin = TOUCH_IRQ_Pin;
  GPIO_InitStruct.Mode = GPIO_MODE_INPUT;
  GPIO_InitStruct.Pull = GPIO_PULLUP;
  HAL_GPIO_Init(TOUCH_IRQ_GPIO_Port, &GPIO_InitStruct);

  /*Configure GPIO pin : TOUCH_CS_Pin */
  GPIO_InitStruct.Pin = TOUCH_CS_Pin;
  GPIO_InitStruct.Mode = GPIO_MODE_OUTPUT_PP;
  GPIO_InitStruct.Pull = GPIO_NOPULL;
  GPIO_InitStruct.Speed = GPIO_SPEED_FREQ_LOW;
  HAL_GPIO_Init(TOUCH_CS_GPIO_Port, &GPIO_InitStruct);

  /*Configure GPIO pins : LCD_DC_Pin LCD_RESET_Pin */
  GPIO_InitStruct.Pin = LCD_DC_Pin|LCD_RESET_Pin;
  GPIO_InitStruct.Mode = GPIO_MODE_OUTPUT_PP;
  GPIO_InitStruct.Pull = GPIO_NOPULL;
  GPIO_InitStruct.Speed = GPIO_SPEED_FREQ_MEDIUM;
  HAL_GPIO_Init(GPIOD, &GPIO_InitStruct);

  /*Configure GPIO pin : CS4270_NRESET_Pin */
  GPIO_InitStruct.Pin = CS4270_NRESET_Pin;
  GPIO_InitStruct.Mode = GPIO_MODE_OUTPUT_PP;
  GPIO_InitStruct.Pull = GPIO_NOPULL;
  GPIO_InitStruct.Speed = GPIO_SPEED_FREQ_LOW;
  HAL_GPIO_Init(CS4270_NRESET_GPIO_Port, &GPIO_InitStruct);

  /*Configure GPIO pin : DBG_PAD1_Pin */
  GPIO_InitStruct.Pin = DBG_PAD1_Pin;
  GPIO_InitStruct.Mode = GPIO_MODE_INPUT;
  GPIO_InitStruct.Pull = GPIO_PULLDOWN;
  HAL_GPIO_Init(DBG_PAD1_GPIO_Port, &GPIO_InitStruct);

  /*Configure GPIO pin : TCA9548A_NRESET_Pin */
  GPIO_InitStruct.Pin = TCA9548A_NRESET_Pin;
  GPIO_InitStruct.Mode = GPIO_MODE_OUTPUT_PP;
  GPIO_InitStruct.Pull = GPIO_NOPULL;
  GPIO_InitStruct.Speed = GPIO_SPEED_FREQ_LOW;
  HAL_GPIO_Init(TCA9548A_NRESET_GPIO_Port, &GPIO_InitStruct);

}

/* MPU Configuration */

void MPU_Config(void)
{
  MPU_Region_InitTypeDef MPU_InitStruct = {0};

  /* Disables the MPU */
  HAL_MPU_Disable();

  /** Initializes and configures the Region and the memory to be protected
  */
  MPU_InitStruct.Enable = MPU_REGION_ENABLE;
  MPU_InitStruct.Number = MPU_REGION_NUMBER0;
  MPU_InitStruct.BaseAddress = 0x0;
  MPU_InitStruct.Size = MPU_REGION_SIZE_4GB;
  MPU_InitStruct.SubRegionDisable = 0x87;
  MPU_InitStruct.TypeExtField = MPU_TEX_LEVEL0;
  MPU_InitStruct.AccessPermission = MPU_REGION_NO_ACCESS;
  MPU_InitStruct.DisableExec = MPU_INSTRUCTION_ACCESS_DISABLE;
  MPU_InitStruct.IsShareable = MPU_ACCESS_NOT_SHAREABLE;
  MPU_InitStruct.IsCacheable = MPU_ACCESS_NOT_CACHEABLE;
  MPU_InitStruct.IsBufferable = MPU_ACCESS_NOT_BUFFERABLE;

  HAL_MPU_ConfigRegion(&MPU_InitStruct);

  /** Initializes and configures the Region and the memory to be protected
  */
  MPU_InitStruct.Number = MPU_REGION_NUMBER1;
  MPU_InitStruct.BaseAddress = 0x24000000;
  MPU_InitStruct.Size = MPU_REGION_SIZE_512KB;
  MPU_InitStruct.SubRegionDisable = 0x0;
  MPU_InitStruct.TypeExtField = MPU_TEX_LEVEL1;
  MPU_InitStruct.AccessPermission = MPU_REGION_FULL_ACCESS;
  MPU_InitStruct.IsCacheable = MPU_ACCESS_CACHEABLE;
  MPU_InitStruct.IsBufferable = MPU_ACCESS_BUFFERABLE;

  HAL_MPU_ConfigRegion(&MPU_InitStruct);

  /** Initializes and configures the Region and the memory to be protected
  */
  MPU_InitStruct.Number = MPU_REGION_NUMBER2;
  MPU_InitStruct.BaseAddress = 0xC0000000;
  MPU_InitStruct.Size = MPU_REGION_SIZE_32MB;
  MPU_InitStruct.TypeExtField = MPU_TEX_LEVEL0;
  MPU_InitStruct.IsBufferable = MPU_ACCESS_NOT_BUFFERABLE;

  HAL_MPU_ConfigRegion(&MPU_InitStruct);
  /* Enables the MPU */
  HAL_MPU_Enable(MPU_PRIVILEGED_DEFAULT);

}

void Error_Handler(void)
{
  __disable_irq();
  while (1)
  {
  }
}
